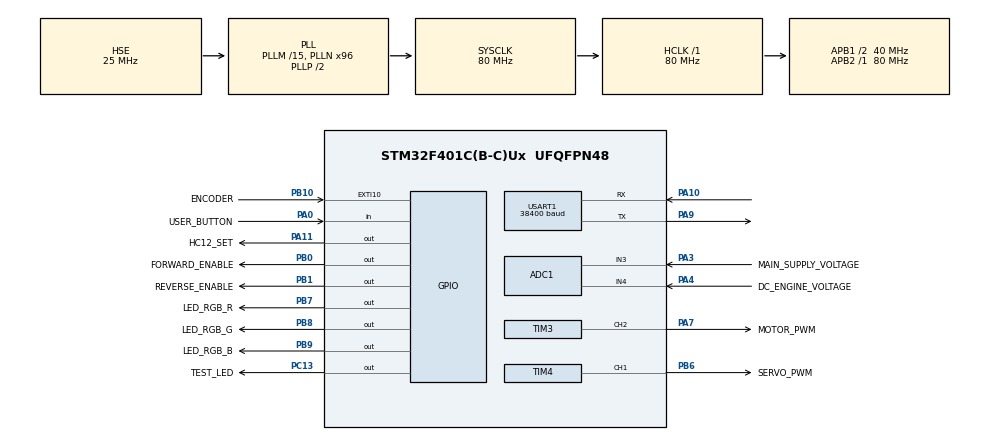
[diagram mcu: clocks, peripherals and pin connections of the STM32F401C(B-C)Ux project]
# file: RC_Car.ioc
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ADC1.Channel-0\#ChannelRegularConversion=ADC_CHANNEL_3
ADC1.Channel-1\#ChannelRegularConversion=ADC_CHANNEL_4
ADC1.ContinuousConvMode=ENABLE
ADC1.DMAContinuousRequests=ENABLE
ADC1.EOCSelection=ADC_EOC_SEQ_CONV
ADC1.NbrOfConversion=2
ADC1.NbrOfConversionFlag=1
ADC1.Rank-0\#ChannelRegularConversion=1
ADC1.Rank-1\#ChannelRegularConversion=2
ADC1.SamplingTime-0\#ChannelRegularConversion=ADC_SAMPLETIME_480CYCLES
ADC1.SamplingTime-1\#ChannelRegularConversion=ADC_SAMPLETIME_480CYCLES
ADC1.master=1
Dma.ADC1.0.Direction=DMA_PERIPH_TO_MEMORY
Dma.ADC1.0.FIFOMode=DMA_FIFOMODE_DISABLE
Dma.ADC1.0.Instance=DMA2_Stream0
Dma.ADC1.0.MemDataAlignment=DMA_MDATAALIGN_HALFWORD
Dma.ADC1.0.MemInc=DMA_MINC_ENABLE
Dma.ADC1.0.Mode=DMA_CIRCULAR
Dma.ADC1.0.PeriphDataAlignment=DMA_PDATAALIGN_HALFWORD
Dma.ADC1.0.PeriphInc=DMA_PINC_DISABLE
Dma.ADC1.0.Priority=DMA_PRIORITY_LOW
Dma.Request0=ADC1
Mcu.Family=STM32F4
Mcu.Name=STM32F401C(B-C)Ux
Mcu.Package=UFQFPN48
NVIC.DMA2_Stream0_IRQn=true\:0\:0\:false\:false\:true\:false\:true\:true
NVIC.EXTI15_10_IRQn=true\:2\:0\:true\:false\:true\:true\:true\:true
NVIC.PriorityGroup=NVIC_PRIORITYGROUP_2
NVIC.TIM2_IRQn=true\:1\:0\:true\:false\:true\:true\:true\:true
NVIC.USART1_IRQn=true\:2\:0\:true\:false\:true\:true\:true\:true
PA0-WKUP.GPIO_Label=USER_BUTTON
PA0-WKUP.GPIO_PuPd=GPIO_PULLUP
PA0-WKUP.Signal=GPIO_Input
PA10.Mode=Asynchronous
PA10.Signal=USART1_RX
PA11.GPIO_Label=HC12_SET
PA11.GPIO_PuPd=GPIO_PULLUP
PA11.Signal=GPIO_Output
PA3.GPIO_Label=MAIN_SUPPLY_VOLTAGE
PA3.Signal=ADCx_IN3
PA4.GPIO_Label=DC_ENGINE_VOLTAGE
PA4.Signal=ADCx_IN4
PA7.GPIO_Label=MOTOR_PWM
PA7.Signal=S_TIM3_CH2
PA9.Mode=Asynchronous
PA9.Signal=USART1_TX
PB0.GPIO_Label=FORWARD_ENABLE
PB0.GPIO_PuPd=GPIO_PULLDOWN
PB0.Signal=GPIO_Output
PB1.GPIO_Label=REVERSE_ENABLE
PB1.GPIO_PuPd=GPIO_PULLDOWN
PB1.Signal=GPIO_Output
PB10.GPIO_Label=ENCODER
PB10.GPIO_ModeDefaultEXTI=GPIO_MODE_IT_RISING
PB10.GPIO_PuPd=GPIO_PULLDOWN
PB10.Signal=GPXTI10
PB6.GPIO_Label=SERVO_PWM
PB6.Signal=S_TIM4_CH1
PB7.GPIO_Label=LED_RGB_R
PB7.GPIO_PuPd=GPIO_PULLDOWN
PB7.Signal=GPIO_Output
PB8.GPIO_Label=LED_RGB_G
PB8.GPIO_PuPd=GPIO_PULLDOWN
PB8.Signal=GPIO_Output
PB9.GPIO_Label=LED_RGB_B
PB9.GPIO_PuPd=GPIO_PULLDOWN
PB9.Signal=GPIO_Output
PC13-ANTI_TAMP.GPIO_Label=TEST_LED
PC13-ANTI_TAMP.GPIO_PuPd=GPIO_PULLUP
PC13-ANTI_TAMP.Signal=GPIO_Output
PC14-OSC32_IN.Mode=LSE-External-Oscillator
PC14-OSC32_IN.Signal=RCC_OSC32_IN
PC15-OSC32_OUT.Mode=LSE-External-Oscillator
PC15-OSC32_OUT.Signal=RCC_OSC32_OUT
PH0\ -\ OSC_IN.Mode=HSE-External-Oscillator
PH0\ -\ OSC_IN.Signal=RCC_OSC_IN
PH1\ -\ OSC_OUT.Mode=HSE-External-Oscillator
PH1\ -\ OSC_OUT.Signal=RCC_OSC_OUT
ProjectManager.HeapSize=0x200
ProjectManager.StackSize=0x400
ProjectManager.TargetToolchain=Makefile
RCC.48MHZClocksFreq_Value=40000000
RCC.AHBFreq_Value=80000000
RCC.APB1CLKDivider=RCC_HCLK_DIV2
RCC.APB1Freq_Value=40000000
RCC.APB1TimFreq_Value=80000000
RCC.APB2Freq_Value=80000000
RCC.APB2TimFreq_Value=80000000
RCC.CortexFreq_Value=80000000
RCC.HCLKFreq_Value=80000000
RCC.HSE_VALUE=25000000
RCC.HSI_VALUE=16000000
RCC.PLLM=15
RCC.PLLN=96
RCC.PLLSourceVirtual=RCC_PLLSOURCE_HSE
RCC.RCC_RTC_Clock_Source=RCC_RTCCLKSOURCE_LSE
RCC.RCC_RTC_Clock_SourceVirtual=RCC_RTCCLKSOURCE_LSE
RCC.SYSCLKFreq_VALUE=80000000
RCC.SYSCLKSource=RCC_SYSCLKSOURCE_PLLCLK
RCC.VCOOutputFreq_Value=160000000
SH.ADCx_IN3.0=ADC1_IN3,IN3
SH.ADCx_IN4.0=ADC1_IN4,IN4
SH.S_TIM3_CH2.0=TIM3_CH2,PWM Generation2 CH2
SH.S_TIM4_CH1.0=TIM4_CH1,PWM Generation1 CH1
TIM2.Period=9
TIM2.Prescaler=79
TIM3.Channel-PWM\ Generation2\ CH2=TIM_CHANNEL_2
TIM3.OCPolarity_2=TIM_OCPOLARITY_HIGH
TIM3.Period=99
TIM3.Prescaler=2666
TIM4.Channel-PWM\ Generation1\ CH1=TIM_CHANNEL_1
TIM4.Period=19999
TIM4.Prescaler=79
USART1.BaudRate=38400
USART1.VirtualMode=VM_ASYNC
VP_RTC_VS_RTC_Activate.Mode=RTC_Enabled
VP_RTC_VS_RTC_Calendar.Mode=RTC_Calendar
VP_TIM2_VS_ClockSourceINT.Mode=Internal
VP_TIM3_VS_ClockSourceINT.Mode=Internal
VP_TIM4_VS_ClockSourceINT.Mode=Internal
board=custom

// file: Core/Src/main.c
/* USER CODE BEGIN Header */
/**
 ******************************************************************************
 * @file           : main.c
 * @brief          : Main program body
 ******************************************************************************
 * @attention
 *
 * Copyright (c) 2024 STMicroelectronics.
 * All rights reserved.
 *
 * This software is licensed under terms that can be found in the LICENSE file
 * in the root directory of this software component.
 * If no LICENSE file comes with this software, it is provided AS-IS.
 *
 ******************************************************************************
 */
/* USER CODE END Header */
#include "main.h"
#include "adc.h"
#include "dma.h"
#include "rtc.h"
#include "tim.h"
#include "usart.h"
#include "gpio.h"

void SystemClock_Config(void);

/* USER CODE BEGIN 0 */
void appStart();
void appMainLoop();
/* USER CODE END 0 */

int main(void)
{

  /* MCU Configuration--------------------------------------------------------*/

  /* Reset of all peripherals, Initializes the Flash interface and the Systick. */
  HAL_Init();

  /* Configure the system clock */
  SystemClock_Config();

  /* Initialize all configured peripherals */
  MX_GPIO_Init();
  MX_DMA_Init();
  MX_USART1_UART_Init();
  MX_TIM2_Init();
  MX_ADC1_Init();
  MX_TIM3_Init();
  MX_TIM4_Init();
  MX_RTC_Init();
  /* USER CODE BEGIN 2 */
  appStart();
  /* USER CODE END 2 */

  /* Infinite loop */
  /* USER CODE BEGIN WHILE */
  while (1) {
    appMainLoop();
    /* USER CODE END WHILE */

  }
}

void SystemClock_Config(void)
{
  RCC_OscInitTypeDef RCC_OscInitStruct = {0};
  RCC_ClkInitTypeDef RCC_ClkInitStruct = {0};

  /** Configure the main internal regulator output voltage
  */
  __HAL_RCC_PWR_CLK_ENABLE();
  __HAL_PWR_VOLTAGESCALING_CONFIG(PWR_REGULATOR_VOLTAGE_SCALE2);

  /** Initializes the RCC Oscillators according to the specified parameters
  * in the RCC_OscInitTypeDef structure.
  */
  RCC_OscInitStruct.OscillatorType = RCC_OSCILLATORTYPE_HSE|RCC_OSCILLATORTYPE_LSE;
  RCC_OscInitStruct.HSEState = RCC_HSE_ON;
  RCC_OscInitStruct.LSEState = RCC_LSE_ON;
  RCC_OscInitStruct.PLL.PLLState = RCC_PLL_ON;
  RCC_OscInitStruct.PLL.PLLSource = RCC_PLLSOURCE_HSE;
  RCC_OscInitStruct.PLL.PLLM = 15;
  RCC_OscInitStruct.PLL.PLLN = 96;
  RCC_OscInitStruct.PLL.PLLP = RCC_PLLP_DIV2;
  RCC_OscInitStruct.PLL.PLLQ = 4;
  if (HAL_RCC_OscConfig(&RCC_OscInitStruct) != HAL_OK)
  {
    Error_Handler();
  }

  /** Initializes the CPU, AHB and APB buses clocks
  */
  RCC_ClkInitStruct.ClockType = RCC_CLOCKTYPE_HCLK|RCC_CLOCKTYPE_SYSCLK
                              |RCC_CLOCKTYPE_PCLK1|RCC_CLOCKTYPE_PCLK2;
  RCC_ClkInitStruct.SYSCLKSource = RCC_SYSCLKSOURCE_PLLCLK;
  RCC_ClkInitStruct.AHBCLKDivider = RCC_SYSCLK_DIV1;
  RCC_ClkInitStruct.APB1CLKDivider = RCC_HCLK_DIV2;
  RCC_ClkInitStruct.APB2CLKDivider = RCC_HCLK_DIV1;

  if (HAL_RCC_ClockConfig(&RCC_ClkInitStruct, FLASH_LATENCY_2) != HAL_OK)
  {
    Error_Handler();
  }
}

void Error_Handler(void)
{
  __disable_irq();
  while (1) {
  }
}
